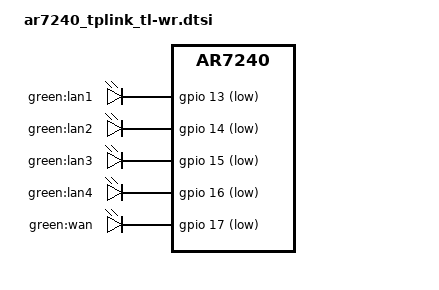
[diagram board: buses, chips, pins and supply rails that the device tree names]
// SPDX-License-Identifier: GPL-2.0-or-later OR MIT

#include "ar7240_tplink.dtsi"

&leds {
	lan1 {
		label = "green:lan1";
		gpios = <&gpio 13 GPIO_ACTIVE_LOW>;
	};

	lan2 {
		label = "green:lan2";
		gpios = <&gpio 14 GPIO_ACTIVE_LOW>;
	};

	lan3 {
		label = "green:lan3";
		gpios = <&gpio 15 GPIO_ACTIVE_LOW>;
	};

	lan4 {
		label = "green:lan4";
		gpios = <&gpio 16 GPIO_ACTIVE_LOW>;
	};

	wan {
		label = "green:wan";
		gpios = <&gpio 17 GPIO_ACTIVE_LOW>;
	};
};

&eth0 {
	mtd-mac-address = <&uboot 0x1fc00>;
	mtd-mac-address-increment = <(-1)>;
};

&eth1 {
	mtd-mac-address = <&uboot 0x1fc00>;
	mtd-mac-address-increment = <1>;
};

&ath9k {
	compatible = "pci168c,002b";
};
